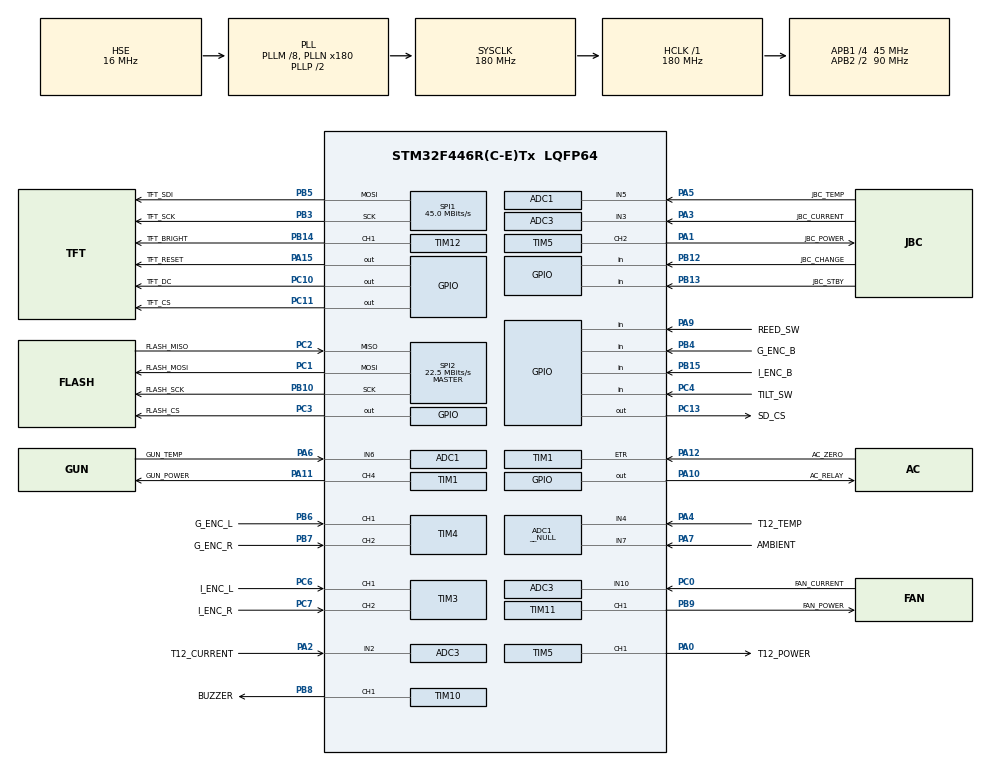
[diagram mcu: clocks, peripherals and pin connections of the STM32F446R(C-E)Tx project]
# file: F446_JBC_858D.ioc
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ADC1.Channel-1\#ChannelRegularConversion=ADC_CHANNEL_4
ADC1.Channel-2\#ChannelRegularConversion=ADC_CHANNEL_7
ADC1.Channel-3\#ChannelRegularConversion=ADC_CHANNEL_VREFINT
ADC1.Channel-4\#ChannelRegularConversion=ADC_CHANNEL_TEMPSENSOR
ADC1.ClockPrescaler=ADC_CLOCK_SYNC_PCLK_DIV4
ADC1.ContinuousConvMode=DISABLE
ADC1.Mode=__NULL
ADC1.NbrOfConversion=4
ADC1.NbrOfConversionFlag=1
ADC1.Rank-1\#ChannelRegularConversion=1
ADC1.Rank-2\#ChannelRegularConversion=2
ADC1.Rank-3\#ChannelRegularConversion=3
ADC1.Rank-4\#ChannelRegularConversion=4
ADC1.SamplingTime-1\#ChannelRegularConversion=ADC_SAMPLETIME_480CYCLES
ADC1.SamplingTime-2\#ChannelRegularConversion=ADC_SAMPLETIME_480CYCLES
ADC1.SamplingTime-3\#ChannelRegularConversion=ADC_SAMPLETIME_480CYCLES
ADC1.SamplingTime-4\#ChannelRegularConversion=ADC_SAMPLETIME_480CYCLES
ADC1.master=1
ADC2.Channel-0\#ChannelRegularConversion=ADC_CHANNEL_5
ADC2.Channel-1\#ChannelRegularConversion=ADC_CHANNEL_6
ADC2.ContinuousConvMode=DISABLE
ADC2.NbrOfConversion=2
ADC2.NbrOfConversionFlag=1
ADC2.Rank-0\#ChannelRegularConversion=1
ADC2.Rank-1\#ChannelRegularConversion=2
ADC2.SamplingTime-0\#ChannelRegularConversion=ADC_SAMPLETIME_480CYCLES
ADC2.SamplingTime-1\#ChannelRegularConversion=ADC_SAMPLETIME_144CYCLES
ADC3.Channel-0\#ChannelRegularConversion=ADC_CHANNEL_2
ADC3.Channel-1\#ChannelRegularConversion=ADC_CHANNEL_3
ADC3.Channel-2\#ChannelRegularConversion=ADC_CHANNEL_10
ADC3.NbrOfConversion=3
ADC3.NbrOfConversionFlag=1
ADC3.Rank-0\#ChannelRegularConversion=1
ADC3.Rank-1\#ChannelRegularConversion=2
ADC3.Rank-2\#ChannelRegularConversion=3
ADC3.SamplingTime-0\#ChannelRegularConversion=ADC_SAMPLETIME_144CYCLES
ADC3.SamplingTime-1\#ChannelRegularConversion=ADC_SAMPLETIME_144CYCLES
ADC3.SamplingTime-2\#ChannelRegularConversion=ADC_SAMPLETIME_144CYCLES
Dma.ADC1.1.Direction=DMA_PERIPH_TO_MEMORY
Dma.ADC1.1.FIFOMode=DMA_FIFOMODE_DISABLE
Dma.ADC1.1.Instance=DMA2_Stream0
Dma.ADC1.1.MemDataAlignment=DMA_MDATAALIGN_HALFWORD
Dma.ADC1.1.MemInc=DMA_MINC_ENABLE
Dma.ADC1.1.Mode=DMA_NORMAL
Dma.ADC1.1.PeriphDataAlignment=DMA_PDATAALIGN_HALFWORD
Dma.ADC1.1.PeriphInc=DMA_PINC_DISABLE
Dma.ADC1.1.Priority=DMA_PRIORITY_LOW
Dma.ADC2.3.Direction=DMA_PERIPH_TO_MEMORY
Dma.ADC2.3.FIFOMode=DMA_FIFOMODE_DISABLE
Dma.ADC2.3.Instance=DMA2_Stream2
Dma.ADC2.3.MemDataAlignment=DMA_MDATAALIGN_HALFWORD
Dma.ADC2.3.MemInc=DMA_MINC_ENABLE
Dma.ADC2.3.Mode=DMA_NORMAL
Dma.ADC2.3.PeriphDataAlignment=DMA_PDATAALIGN_HALFWORD
Dma.ADC2.3.PeriphInc=DMA_PINC_DISABLE
Dma.ADC2.3.Priority=DMA_PRIORITY_LOW
Dma.ADC3.0.Direction=DMA_PERIPH_TO_MEMORY
Dma.ADC3.0.FIFOMode=DMA_FIFOMODE_DISABLE
Dma.ADC3.0.Instance=DMA2_Stream1
Dma.ADC3.0.MemDataAlignment=DMA_MDATAALIGN_HALFWORD
Dma.ADC3.0.MemInc=DMA_MINC_ENABLE
Dma.ADC3.0.Mode=DMA_NORMAL
Dma.ADC3.0.PeriphDataAlignment=DMA_PDATAALIGN_HALFWORD
Dma.ADC3.0.PeriphInc=DMA_PINC_DISABLE
Dma.ADC3.0.Priority=DMA_PRIORITY_LOW
Dma.Request0=ADC3
Dma.Request1=ADC1
Dma.Request2=SPI1_TX
Dma.Request3=ADC2
Dma.Request4=TIM1_CH4/TRIG/COM
Dma.SPI1_TX.2.Direction=DMA_MEMORY_TO_PERIPH
Dma.SPI1_TX.2.FIFOMode=DMA_FIFOMODE_DISABLE
Dma.SPI1_TX.2.Instance=DMA2_Stream3
Dma.SPI1_TX.2.MemDataAlignment=DMA_MDATAALIGN_BYTE
Dma.SPI1_TX.2.MemInc=DMA_MINC_ENABLE
Dma.SPI1_TX.2.Mode=DMA_NORMAL
Dma.SPI1_TX.2.PeriphDataAlignment=DMA_PDATAALIGN_BYTE
Dma.SPI1_TX.2.PeriphInc=DMA_PINC_DISABLE
Dma.SPI1_TX.2.Priority=DMA_PRIORITY_LOW
Dma.TIM1_CH4/TRIG/COM.4.Direction=DMA_MEMORY_TO_PERIPH
Dma.TIM1_CH4/TRIG/COM.4.FIFOMode=DMA_FIFOMODE_DISABLE
Dma.TIM1_CH4/TRIG/COM.4.Instance=DMA2_Stream4
Dma.TIM1_CH4/TRIG/COM.4.MemDataAlignment=DMA_MDATAALIGN_HALFWORD
Dma.TIM1_CH4/TRIG/COM.4.MemInc=DMA_MINC_ENABLE
Dma.TIM1_CH4/TRIG/COM.4.Mode=DMA_CIRCULAR
Dma.TIM1_CH4/TRIG/COM.4.PeriphDataAlignment=DMA_PDATAALIGN_HALFWORD
Dma.TIM1_CH4/TRIG/COM.4.PeriphInc=DMA_PINC_DISABLE
Dma.TIM1_CH4/TRIG/COM.4.Priority=DMA_PRIORITY_LOW
Mcu.Family=STM32F4
Mcu.Name=STM32F446R(C-E)Tx
Mcu.Package=LQFP64
NVIC.DMA2_Stream0_IRQn=true\:0\:0\:false\:false\:true\:false\:true\:true
NVIC.DMA2_Stream1_IRQn=true\:0\:0\:false\:false\:true\:false\:true\:true
NVIC.DMA2_Stream2_IRQn=true\:0\:0\:false\:false\:true\:false\:true\:true
NVIC.DMA2_Stream3_IRQn=true\:2\:0\:true\:false\:true\:false\:true\:true
NVIC.DMA2_Stream4_IRQn=true\:0\:0\:false\:false\:true\:false\:true\:true
NVIC.PriorityGroup=NVIC_PRIORITYGROUP_4
NVIC.TIM1_UP_TIM10_IRQn=true\:0\:0\:false\:false\:true\:true\:true\:true
NVIC.TIM5_IRQn=true\:0\:0\:false\:false\:true\:true\:true\:true
NVIC.TIM7_IRQn=true\:0\:0\:false\:false\:true\:true\:true\:true
PA0-WKUP.GPIO_Label=T12_POWER
PA0-WKUP.Signal=S_TIM5_CH1
PA1.GPIO_Label=JBC_POWER
PA1.Signal=S_TIM5_CH2
PA10.GPIO_Label=AC_RELAY
PA10.Signal=GPIO_Output
PA11.GPIO_Label=GUN_POWER
PA11.Signal=S_TIM1_CH4
PA12.GPIO_Label=AC_ZERO
PA12.Signal=S_TIM1_ETR
PA13.Mode=Serial_Wire
PA13.Signal=SYS_JTMS-SWDIO
PA14.Mode=Serial_Wire
PA14.Signal=SYS_JTCK-SWCLK
PA15.GPIO_Label=TFT_RESET
PA15.Signal=GPIO_Output
PA2.GPIO_Label=T12_CURRENT
PA2.Signal=ADCx_IN2
PA3.GPIO_Label=JBC_CURRENT
PA3.Signal=ADCx_IN3
PA4.GPIO_Label=T12_TEMP
PA4.Signal=ADCx_IN4
PA5.GPIO_Label=JBC_TEMP
PA5.Signal=ADCx_IN5
PA6.GPIO_Label=GUN_TEMP
PA6.Signal=ADCx_IN6
PA7.GPIO_Label=AMBIENT
PA7.Signal=ADCx_IN7
PA9.GPIO_Label=REED_SW
PA9.Signal=GPIO_Input
PB10.GPIO_Label=FLASH_SCK
PB10.Mode=Full_Duplex_Master
PB10.Signal=SPI2_SCK
PB12.GPIO_Label=JBC_CHANGE
PB12.Signal=GPIO_Input
PB13.GPIO_Label=JBC_STBY
PB13.Signal=GPIO_Input
PB14.GPIO_Label=TFT_BRIGHT
PB14.Signal=S_TIM12_CH1
PB15.GPIO_Label=I_ENC_B
PB15.Signal=GPIO_Input
PB3.GPIO_Label=TFT_SCK
PB3.Mode=TX_Only_Simplex_Unidirect_Master
PB3.Signal=SPI1_SCK
PB4.GPIO_Label=G_ENC_B
PB4.Signal=GPIO_Input
PB5.GPIO_Label=TFT_SDI
PB5.Mode=TX_Only_Simplex_Unidirect_Master
PB5.Signal=SPI1_MOSI
PB6.GPIO_Label=G_ENC_L
PB6.Signal=S_TIM4_CH1
PB7.GPIO_Label=G_ENC_R
PB7.Signal=S_TIM4_CH2
PB8.GPIO_Label=BUZZER
PB8.Signal=S_TIM10_CH1
PB9.GPIO_Label=FAN_POWER
PB9.Signal=S_TIM11_CH1
PC0.GPIO_Label=FAN_CURRENT
PC0.Signal=ADCx_IN10
PC1.GPIO_Label=FLASH_MOSI
PC1.Mode=Full_Duplex_Master
PC1.Signal=SPI2_MOSI
PC10.GPIO_Label=TFT_DC
PC10.Signal=GPIO_Output
PC11.GPIO_Label=TFT_CS
PC11.Signal=GPIO_Output
PC13.GPIO_Label=SD_CS
PC13.Signal=GPIO_Output
PC2.GPIO_Label=FLASH_MISO
PC2.Mode=Full_Duplex_Master
PC2.Signal=SPI2_MISO
PC3.GPIO_Label=FLASH_CS
PC3.Signal=GPIO_Output
PC4.GPIO_Label=TILT_SW
PC4.Signal=GPIO_Input
PC6.GPIO_Label=I_ENC_L
PC6.Signal=S_TIM3_CH1
PC7.GPIO_Label=I_ENC_R
PC7.Signal=S_TIM3_CH2
PH0-OSC_IN.Mode=HSE-External-Oscillator
PH0-OSC_IN.Signal=RCC_OSC_IN
PH1-OSC_OUT.Mode=HSE-External-Oscillator
PH1-OSC_OUT.Signal=RCC_OSC_OUT
ProjectManager.HeapSize=0x200
ProjectManager.StackSize=0x400
ProjectManager.TargetToolchain=STM32CubeIDE
RCC.AHBFreq_Value=180000000
RCC.APB1CLKDivider=RCC_HCLK_DIV4
RCC.APB1Freq_Value=45000000
RCC.APB1TimFreq_Value=90000000
RCC.APB2CLKDivider=RCC_HCLK_DIV2
RCC.APB2Freq_Value=90000000
RCC.APB2TimFreq_Value=180000000
RCC.CortexFreq_Value=180000000
RCC.HCLKFreq_Value=180000000
RCC.HSE_VALUE=16000000
RCC.PLLM=8
RCC.PLLN=180
RCC.PLLSourceVirtual=RCC_PLLSOURCE_HSE
RCC.SYSCLKFreq_VALUE=180000000
RCC.SYSCLKSource=RCC_SYSCLKSOURCE_PLLCLK
RCC.USBFreq_Value=180000000
RCC.VCOOutputFreq_Value=360000000
SH.ADCx_IN10.0=ADC3_IN10,IN10
SH.ADCx_IN2.0=ADC3_IN2,IN2
SH.ADCx_IN3.0=ADC3_IN3,IN3
SH.ADCx_IN4.0=ADC1_IN4,IN4
SH.ADCx_IN4.1=ADC2_IN4,IN4
SH.ADCx_IN5.0=ADC1_IN5,IN5
SH.ADCx_IN5.1=ADC2_IN5,IN5
SH.ADCx_IN6.0=ADC1_IN6,IN6
SH.ADCx_IN6.1=ADC2_IN6,IN6
SH.ADCx_IN7.0=ADC1_IN7,IN7
SH.ADCx_IN7.1=ADC2_IN7,IN7
SH.S_TIM10_CH1.0=TIM10_CH1,PWM Generation1 CH1
SH.S_TIM11_CH1.0=TIM11_CH1,PWM Generation1 CH1
SH.S_TIM12_CH1.0=TIM12_CH1,PWM Generation1 CH1
SH.S_TIM1_CH4.0=TIM1_CH4,PWM Generation4 CH4
SH.S_TIM1_ETR.0=TIM1_ETR,TriggerSource_ETR
SH.S_TIM3_CH1.0=TIM3_CH1,Encoder_Interface
SH.S_TIM3_CH2.0=TIM3_CH2,Encoder_Interface
SH.S_TIM4_CH1.0=TIM4_CH1,Encoder_Interface
SH.S_TIM4_CH2.0=TIM4_CH2,Encoder_Interface
SH.S_TIM5_CH1.0=TIM5_CH1,PWM Generation1 CH1
SH.S_TIM5_CH2.0=TIM5_CH2,PWM Generation2 CH2
SPI1.BaudRatePrescaler=SPI_BAUDRATEPRESCALER_2
SPI1.CalculateBaudRate=45.0 MBits/s
SPI1.Direction=SPI_DIRECTION_2LINES
SPI1.Mode=SPI_MODE_MASTER
SPI1.VirtualType=VM_MASTER
SPI2.BaudRatePrescaler=SPI_BAUDRATEPRESCALER_2
SPI2.CalculateBaudRate=22.5 MBits/s
SPI2.Direction=SPI_DIRECTION_2LINES
SPI2.Mode=SPI_MODE_MASTER
SPI2.VirtualType=VM_MASTER
TIM1.Channel-PWM\ Generation4\ CH4=TIM_CHANNEL_4
TIM1.ClockDivision=TIM_CLOCKDIVISION_DIV4
TIM1.Period=255
TIM1.Prescaler=17999
TIM1.Slave_TriggerFilter=7
TIM10.Channel=TIM_CHANNEL_1
TIM10.Prescaler=179
TIM11.Channel=TIM_CHANNEL_1
TIM11.Period=1999
TIM11.Prescaler=9
TIM12.Channel-PWM\ Generation1\ CH1=TIM_CHANNEL_1
TIM12.OCPolarity_1=TIM_OCPOLARITY_LOW
TIM12.Period=255
TIM12.Prescaler=777
TIM3.IC1Filter=7
TIM3.IC2Filter=7
TIM4.IC1Filter=7
TIM4.IC2Filter=7
TIM5.Channel-Output\ Compare3\ No\ Output=TIM_CHANNEL_3
TIM5.Channel-Output\ Compare4\ No\ Output=TIM_CHANNEL_4
TIM5.Channel-PWM\ Generation1\ CH1=TIM_CHANNEL_1
TIM5.Channel-PWM\ Generation2\ CH2=TIM_CHANNEL_2
TIM5.Period=1999
TIM5.Prescaler=899
TIM5.Pulse-Output\ Compare3\ No\ Output=1
TIM5.Pulse-Output\ Compare4\ No\ Output=1980
TIM7.Prescaler=8999
VP_ADC1_TempSens_Input.Mode=IN-TempSens
VP_ADC1_Vref_Input.Mode=IN-Vrefint
VP_TIM10_VS_ClockSourceINT.Mode=Enable_Timer
VP_TIM11_VS_ClockSourceINT.Mode=Enable_Timer
VP_TIM12_VS_ClockSourceINT.Mode=Internal
VP_TIM1_VS_ClockSourceINT.Mode=Internal
VP_TIM1_VS_ControllerModeReset.Mode=Reset Mode
VP_TIM5_VS_ClockSourceINT.Mode=Internal
VP_TIM5_VS_no_output3.Mode=Output Compare3 No Output
VP_TIM5_VS_no_output4.Mode=Output Compare4 No Output
VP_TIM7_VS_ClockSourceINT.Mode=Enable_Timer
board=custom

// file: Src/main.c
/* USER CODE BEGIN Header */
/**
  ******************************************************************************
  * @file           : main.c
  * @brief          : Main program body
  ******************************************************************************
  * @attention
  *
  * Copyright (c) 2022 STMicroelectronics.
  * All rights reserved.
  *
  * This software is licensed under terms that can be found in the LICENSE file
  * in the root directory of this software component.
  * If no LICENSE file comes with this software, it is provided AS-IS.
  *
  ******************************************************************************
  *
  * DONE OCT 06 2024, v.1.07:
  *  Fast Hot Gun cooling
  *  The GUN detection bug fixed at GUN PID tune procedure.
  *
  */
/* USER CODE END Header */
#include "main.h"

/* USER CODE BEGIN Includes */
#include "core.h"

/* USER CODE END Includes */

ADC_HandleTypeDef hadc1;
ADC_HandleTypeDef hadc2;
ADC_HandleTypeDef hadc3;
DMA_HandleTypeDef hdma_adc1;
DMA_HandleTypeDef hdma_adc2;
DMA_HandleTypeDef hdma_adc3;

SPI_HandleTypeDef hspi1;
SPI_HandleTypeDef hspi2;
DMA_HandleTypeDef hdma_spi1_tx;

TIM_HandleTypeDef htim1;
TIM_HandleTypeDef htim3;
TIM_HandleTypeDef htim4;
TIM_HandleTypeDef htim5;
TIM_HandleTypeDef htim7;
TIM_HandleTypeDef htim10;
TIM_HandleTypeDef htim11;
TIM_HandleTypeDef htim12;
DMA_HandleTypeDef hdma_tim1_ch4_trig_com;

void SystemClock_Config(void);
static void MX_GPIO_Init(void);
static void MX_DMA_Init(void);
static void MX_ADC1_Init(void);
static void MX_ADC2_Init(void);
static void MX_ADC3_Init(void);
static void MX_TIM1_Init(void);
static void MX_TIM5_Init(void);
static void MX_SPI1_Init(void);
static void MX_SPI2_Init(void);
static void MX_TIM3_Init(void);
static void MX_TIM4_Init(void);
static void MX_TIM10_Init(void);
static void MX_TIM11_Init(void);
static void MX_TIM12_Init(void);
static void MX_TIM7_Init(void);

int main(void)
{

  /* MCU Configuration--------------------------------------------------------*/

  /* Reset of all peripherals, Initializes the Flash interface and the Systick. */
  HAL_Init();

  /* Configure the system clock */
  SystemClock_Config();

  /* Initialize all configured peripherals */
  MX_GPIO_Init();
  MX_DMA_Init();
  MX_ADC1_Init();
  MX_ADC2_Init();
  MX_ADC3_Init();
  MX_TIM1_Init();
  MX_TIM5_Init();
  MX_SPI1_Init();
  MX_SPI2_Init();
  MX_TIM3_Init();
  MX_TIM4_Init();
  MX_TIM10_Init();
  MX_TIM11_Init();
  MX_TIM12_Init();
  MX_TIM7_Init();
  /* USER CODE BEGIN 2 */
  setup();
  /* USER CODE END 2 */

  /* Infinite loop */
  while (1)
  {

    /* USER CODE BEGIN 3 */
	  loop();

  }
  /* USER CODE END 3 */
}

void SystemClock_Config(void)
{
  RCC_OscInitTypeDef RCC_OscInitStruct = {0};
  RCC_ClkInitTypeDef RCC_ClkInitStruct = {0};

  /** Configure the main internal regulator output voltage
  */
  __HAL_RCC_PWR_CLK_ENABLE();
  __HAL_PWR_VOLTAGESCALING_CONFIG(PWR_REGULATOR_VOLTAGE_SCALE1);

  /** Initializes the RCC Oscillators according to the specified parameters
  * in the RCC_OscInitTypeDef structure.
  */
  RCC_OscInitStruct.OscillatorType = RCC_OSCILLATORTYPE_HSE;
  RCC_OscInitStruct.HSEState = RCC_HSE_ON;
  RCC_OscInitStruct.PLL.PLLState = RCC_PLL_ON;
  RCC_OscInitStruct.PLL.PLLSource = RCC_PLLSOURCE_HSE;
  RCC_OscInitStruct.PLL.PLLM = 8;
  RCC_OscInitStruct.PLL.PLLN = 180;
  RCC_OscInitStruct.PLL.PLLP = RCC_PLLP_DIV2;
  RCC_OscInitStruct.PLL.PLLQ = 2;
  RCC_OscInitStruct.PLL.PLLR = 2;
  if (HAL_RCC_OscConfig(&RCC_OscInitStruct) != HAL_OK)
  {
    Error_Handler();
  }

  /** Activate the Over-Drive mode
  */
  if (HAL_PWREx_EnableOverDrive() != HAL_OK)
  {
    Error_Handler();
  }

  /** Initializes the CPU, AHB and APB buses clocks
  */
  RCC_ClkInitStruct.ClockType = RCC_CLOCKTYPE_HCLK|RCC_CLOCKTYPE_SYSCLK
                              |RCC_CLOCKTYPE_PCLK1|RCC_CLOCKTYPE_PCLK2;
  RCC_ClkInitStruct.SYSCLKSource = RCC_SYSCLKSOURCE_PLLCLK;
  RCC_ClkInitStruct.AHBCLKDivider = RCC_SYSCLK_DIV1;
  RCC_ClkInitStruct.APB1CLKDivider = RCC_HCLK_DIV4;
  RCC_ClkInitStruct.APB2CLKDivider = RCC_HCLK_DIV2;

  if (HAL_RCC_ClockConfig(&RCC_ClkInitStruct, FLASH_LATENCY_5) != HAL_OK)
  {
    Error_Handler();
  }
}

static void MX_ADC1_Init(void)
{

  ADC_ChannelConfTypeDef sConfig = {0};

  /** Configure the global features of the ADC (Clock, Resolution, Data Alignment and number of conversion)
  */
  hadc1.Instance = ADC1;
  hadc1.Init.ClockPrescaler = ADC_CLOCK_SYNC_PCLK_DIV4;
  hadc1.Init.Resolution = ADC_RESOLUTION_12B;
  hadc1.Init.ScanConvMode = ENABLE;
  hadc1.Init.ContinuousConvMode = DISABLE;
  hadc1.Init.DiscontinuousConvMode = DISABLE;
  hadc1.Init.ExternalTrigConvEdge = ADC_EXTERNALTRIGCONVEDGE_NONE;
  hadc1.Init.ExternalTrigConv = ADC_SOFTWARE_START;
  hadc1.Init.DataAlign = ADC_DATAALIGN_RIGHT;
  hadc1.Init.NbrOfConversion = 4;
  hadc1.Init.DMAContinuousRequests = DISABLE;
  hadc1.Init.EOCSelection = ADC_EOC_SINGLE_CONV;
  if (HAL_ADC_Init(&hadc1) != HAL_OK)
  {
    Error_Handler();
  }

  /** Configure for the selected ADC regular channel its corresponding rank in the sequencer and its sample time.
  */
  sConfig.Channel = ADC_CHANNEL_4;
  sConfig.Rank = 1;
  sConfig.SamplingTime = ADC_SAMPLETIME_480CYCLES;
  if (HAL_ADC_ConfigChannel(&hadc1, &sConfig) != HAL_OK)
  {
    Error_Handler();
  }

  /** Configure for the selected ADC regular channel its corresponding rank in the sequencer and its sample time.
  */
  sConfig.Channel = ADC_CHANNEL_7;
  sConfig.Rank = 2;
  if (HAL_ADC_ConfigChannel(&hadc1, &sConfig) != HAL_OK)
  {
    Error_Handler();
  }

  /** Configure for the selected ADC regular channel its corresponding rank in the sequencer and its sample time.
  */
  sConfig.Channel = ADC_CHANNEL_VREFINT;
  sConfig.Rank = 3;
  if (HAL_ADC_ConfigChannel(&hadc1, &sConfig) != HAL_OK)
  {
    Error_Handler();
  }

  /** Configure for the selected ADC regular channel its corresponding rank in the sequencer and its sample time.
  */
  sConfig.Channel = ADC_CHANNEL_TEMPSENSOR;
  sConfig.Rank = 4;
  if (HAL_ADC_ConfigChannel(&hadc1, &sConfig) != HAL_OK)
  {
    Error_Handler();
  }

}

static void MX_ADC2_Init(void)
{

  ADC_ChannelConfTypeDef sConfig = {0};

  /** Configure the global features of the ADC (Clock, Resolution, Data Alignment and number of conversion)
  */
  hadc2.Instance = ADC2;
  hadc2.Init.ClockPrescaler = ADC_CLOCK_SYNC_PCLK_DIV4;
  hadc2.Init.Resolution = ADC_RESOLUTION_12B;
  hadc2.Init.ScanConvMode = ENABLE;
  hadc2.Init.ContinuousConvMode = DISABLE;
  hadc2.Init.DiscontinuousConvMode = DISABLE;
  hadc2.Init.ExternalTrigConvEdge = ADC_EXTERNALTRIGCONVEDGE_NONE;
  hadc2.Init.ExternalTrigConv = ADC_SOFTWARE_START;
  hadc2.Init.DataAlign = ADC_DATAALIGN_RIGHT;
  hadc2.Init.NbrOfConversion = 2;
  hadc2.Init.DMAContinuousRequests = DISABLE;
  hadc2.Init.EOCSelection = ADC_EOC_SINGLE_CONV;
  if (HAL_ADC_Init(&hadc2) != HAL_OK)
  {
    Error_Handler();
  }

  /** Configure for the selected ADC regular channel its corresponding rank in the sequencer and its sample time.
  */
  sConfig.Channel = ADC_CHANNEL_5;
  sConfig.Rank = 1;
  sConfig.SamplingTime = ADC_SAMPLETIME_480CYCLES;
  if (HAL_ADC_ConfigChannel(&hadc2, &sConfig) != HAL_OK)
  {
    Error_Handler();
  }

  /** Configure for the selected ADC regular channel its corresponding rank in the sequencer and its sample time.
  */
  sConfig.Channel = ADC_CHANNEL_6;
  sConfig.Rank = 2;
  sConfig.SamplingTime = ADC_SAMPLETIME_144CYCLES;
  if (HAL_ADC_ConfigChannel(&hadc2, &sConfig) != HAL_OK)
  {
    Error_Handler();
  }

}

static void MX_ADC3_Init(void)
{

  ADC_ChannelConfTypeDef sConfig = {0};

  /** Configure the global features of the ADC (Clock, Resolution, Data Alignment and number of conversion)
  */
  hadc3.Instance = ADC3;
  hadc3.Init.ClockPrescaler = ADC_CLOCK_SYNC_PCLK_DIV4;
  hadc3.Init.Resolution = ADC_RESOLUTION_12B;
  hadc3.Init.ScanConvMode = ENABLE;
  hadc3.Init.ContinuousConvMode = DISABLE;
  hadc3.Init.DiscontinuousConvMode = DISABLE;
  hadc3.Init.ExternalTrigConvEdge = ADC_EXTERNALTRIGCONVEDGE_NONE;
  hadc3.Init.ExternalTrigConv = ADC_SOFTWARE_START;
  hadc3.Init.DataAlign = ADC_DATAALIGN_RIGHT;
  hadc3.Init.NbrOfConversion = 3;
  hadc3.Init.DMAContinuousRequests = DISABLE;
  hadc3.Init.EOCSelection = ADC_EOC_SINGLE_CONV;
  if (HAL_ADC_Init(&hadc3) != HAL_OK)
  {
    Error_Handler();
  }

  /** Configure for the selected ADC regular channel its corresponding rank in the sequencer and its sample time.
  */
  sConfig.Channel = ADC_CHANNEL_2;
  sConfig.Rank = 1;
  sConfig.SamplingTime = ADC_SAMPLETIME_144CYCLES;
  if (HAL_ADC_ConfigChannel(&hadc3, &sConfig) != HAL_OK)
  {
    Error_Handler();
  }

  /** Configure for the selected ADC regular channel its corresponding rank in the sequencer and its sample time.
  */
  sConfig.Channel = ADC_CHANNEL_3;
  sConfig.Rank = 2;
  if (HAL_ADC_ConfigChannel(&hadc3, &sConfig) != HAL_OK)
  {
    Error_Handler();
  }

  /** Configure for the selected ADC regular channel its corresponding rank in the sequencer and its sample time.
  */
  sConfig.Channel = ADC_CHANNEL_10;
  sConfig.Rank = 3;
  if (HAL_ADC_ConfigChannel(&hadc3, &sConfig) != HAL_OK)
  {
    Error_Handler();
  }

}

static void MX_SPI1_Init(void)
{

  /* SPI1 parameter configuration*/
  hspi1.Instance = SPI1;
  hspi1.Init.Mode = SPI_MODE_MASTER;
  hspi1.Init.Direction = SPI_DIRECTION_2LINES;
  hspi1.Init.DataSize = SPI_DATASIZE_8BIT;
  hspi1.Init.CLKPolarity = SPI_POLARITY_LOW;
  hspi1.Init.CLKPhase = SPI_PHASE_1EDGE;
  hspi1.Init.NSS = SPI_NSS_SOFT;
  hspi1.Init.BaudRatePrescaler = SPI_BAUDRATEPRESCALER_2;
  hspi1.Init.FirstBit = SPI_FIRSTBIT_MSB;
  hspi1.Init.TIMode = SPI_TIMODE_DISABLE;
  hspi1.Init.CRCCalculation = SPI_CRCCALCULATION_DISABLE;
  hspi1.Init.CRCPolynomial = 10;
  if (HAL_SPI_Init(&hspi1) != HAL_OK)
  {
    Error_Handler();
  }

}

static void MX_SPI2_Init(void)
{

  /* SPI2 parameter configuration*/
  hspi2.Instance = SPI2;
  hspi2.Init.Mode = SPI_MODE_MASTER;
  hspi2.Init.Direction = SPI_DIRECTION_2LINES;
  hspi2.Init.DataSize = SPI_DATASIZE_8BIT;
  hspi2.Init.CLKPolarity = SPI_POLARITY_LOW;
  hspi2.Init.CLKPhase = SPI_PHASE_1EDGE;
  hspi2.Init.NSS = SPI_NSS_SOFT;
  hspi2.Init.BaudRatePrescaler = SPI_BAUDRATEPRESCALER_2;
  hspi2.Init.FirstBit = SPI_FIRSTBIT_MSB;
  hspi2.Init.TIMode = SPI_TIMODE_DISABLE;
  hspi2.Init.CRCCalculation = SPI_CRCCALCULATION_DISABLE;
  hspi2.Init.CRCPolynomial = 10;
  if (HAL_SPI_Init(&hspi2) != HAL_OK)
  {
    Error_Handler();
  }

}

static void MX_TIM1_Init(void)
{

  TIM_ClockConfigTypeDef sClockSourceConfig = {0};
  TIM_SlaveConfigTypeDef sSlaveConfig = {0};
  TIM_MasterConfigTypeDef sMasterConfig = {0};
  TIM_OC_InitTypeDef sConfigOC = {0};
  TIM_BreakDeadTimeConfigTypeDef sBreakDeadTimeConfig = {0};

  htim1.Instance = TIM1;
  htim1.Init.Prescaler = 17999;
  htim1.Init.CounterMode = TIM_COUNTERMODE_UP;
  htim1.Init.Period = 255;
  htim1.Init.ClockDivision = TIM_CLOCKDIVISION_DIV4;
  htim1.Init.RepetitionCounter = 0;
  htim1.Init.AutoReloadPreload = TIM_AUTORELOAD_PRELOAD_DISABLE;
  if (HAL_TIM_Base_Init(&htim1) != HAL_OK)
  {
    Error_Handler();
  }
  sClockSourceConfig.ClockSource = TIM_CLOCKSOURCE_INTERNAL;
  if (HAL_TIM_ConfigClockSource(&htim1, &sClockSourceConfig) != HAL_OK)
  {
    Error_Handler();
  }
  if (HAL_TIM_PWM_Init(&htim1) != HAL_OK)
  {
    Error_Handler();
  }
  sSlaveConfig.SlaveMode = TIM_SLAVEMODE_RESET;
  sSlaveConfig.InputTrigger = TIM_TS_ETRF;
  sSlaveConfig.TriggerPolarity = TIM_TRIGGERPOLARITY_NONINVERTED;
  sSlaveConfig.TriggerPrescaler = TIM_TRIGGERPRESCALER_DIV1;
  sSlaveConfig.TriggerFilter = 7;
  if (HAL_TIM_SlaveConfigSynchro(&htim1, &sSlaveConfig) != HAL_OK)
  {
    Error_Handler();
  }
  sMasterConfig.MasterOutputTrigger = TIM_TRGO_RESET;
  sMasterConfig.MasterSlaveMode = TIM_MASTERSLAVEMODE_DISABLE;
  if (HAL_TIMEx_MasterConfigSynchronization(&htim1, &sMasterConfig) != HAL_OK)
  {
    Error_Handler();
  }
  sConfigOC.OCMode = TIM_OCMODE_PWM1;
  sConfigOC.Pulse = 0;
  sConfigOC.OCPolarity = TIM_OCPOLARITY_HIGH;
  sConfigOC.OCFastMode = TIM_OCFAST_DISABLE;
  sConfigOC.OCIdleState = TIM_OCIDLESTATE_RESET;
  sConfigOC.OCNIdleState = TIM_OCNIDLESTATE_RESET;
  if (HAL_TIM_PWM_ConfigChannel(&htim1, &sConfigOC, TIM_CHANNEL_4) != HAL_OK)
  {
    Error_Handler();
  }
  sBreakDeadTimeConfig.OffStateRunMode = TIM_OSSR_DISABLE;
  sBreakDeadTimeConfig.OffStateIDLEMode = TIM_OSSI_DISABLE;
  sBreakDeadTimeConfig.LockLevel = TIM_LOCKLEVEL_OFF;
  sBreakDeadTimeConfig.DeadTime = 0;
  sBreakDeadTimeConfig.BreakState = TIM_BREAK_DISABLE;
  sBreakDeadTimeConfig.BreakPolarity = TIM_BREAKPOLARITY_HIGH;
  sBreakDeadTimeConfig.AutomaticOutput = TIM_AUTOMATICOUTPUT_DISABLE;
  if (HAL_TIMEx_ConfigBreakDeadTime(&htim1, &sBreakDeadTimeConfig) != HAL_OK)
  {
    Error_Handler();
  }
  HAL_TIM_MspPostInit(&htim1);

}

static void MX_TIM3_Init(void)
{

  TIM_Encoder_InitTypeDef sConfig = {0};
  TIM_MasterConfigTypeDef sMasterConfig = {0};

  htim3.Instance = TIM3;
  htim3.Init.Prescaler = 0;
  htim3.Init.CounterMode = TIM_COUNTERMODE_UP;
  htim3.Init.Period = 65535;
  htim3.Init.ClockDivision = TIM_CLOCKDIVISION_DIV1;
  htim3.Init.AutoReloadPreload = TIM_AUTORELOAD_PRELOAD_DISABLE;
  sConfig.EncoderMode = TIM_ENCODERMODE_TI1;
  sConfig.IC1Polarity = TIM_ICPOLARITY_RISING;
  sConfig.IC1Selection = TIM_ICSELECTION_DIRECTTI;
  sConfig.IC1Prescaler = TIM_ICPSC_DIV1;
  sConfig.IC1Filter = 7;
  sConfig.IC2Polarity = TIM_ICPOLARITY_RISING;
  sConfig.IC2Selection = TIM_ICSELECTION_DIRECTTI;
  sConfig.IC2Prescaler = TIM_ICPSC_DIV1;
  sConfig.IC2Filter = 7;
  if (HAL_TIM_Encoder_Init(&htim3, &sConfig) != HAL_OK)
  {
    Error_Handler();
  }
  sMasterConfig.MasterOutputTrigger = TIM_TRGO_RESET;
  sMasterConfig.MasterSlaveMode = TIM_MASTERSLAVEMODE_DISABLE;
  if (HAL_TIMEx_MasterConfigSynchronization(&htim3, &sMasterConfig) != HAL_OK)
  {
    Error_Handler();
  }

}

static void MX_TIM4_Init(void)
{

  TIM_Encoder_InitTypeDef sConfig = {0};
  TIM_MasterConfigTypeDef sMasterConfig = {0};

  htim4.Instance = TIM4;
  htim4.Init.Prescaler = 0;
  htim4.Init.CounterMode = TIM_COUNTERMODE_UP;
  htim4.Init.Period = 65535;
  htim4.Init.ClockDivision = TIM_CLOCKDIVISION_DIV1;
  htim4.Init.AutoReloadPreload = TIM_AUTORELOAD_PRELOAD_DISABLE;
  sConfig.EncoderMode = TIM_ENCODERMODE_TI1;
  sConfig.IC1Polarity = TIM_ICPOLARITY_RISING;
  sConfig.IC1Selection = TIM_ICSELECTION_DIRECTTI;
  sConfig.IC1Prescaler = TIM_ICPSC_DIV1;
  sConfig.IC1Filter = 7;
  sConfig.IC2Polarity = TIM_ICPOLARITY_RISING;
  sConfig.IC2Selection = TIM_ICSELECTION_DIRECTTI;
  sConfig.IC2Prescaler = TIM_ICPSC_DIV1;
  sConfig.IC2Filter = 7;
  if (HAL_TIM_Encoder_Init(&htim4, &sConfig) != HAL_OK)
  {
    Error_Handler();
  }
  sMasterConfig.MasterOutputTrigger = TIM_TRGO_RESET;
  sMasterConfig.MasterSlaveMode = TIM_MASTERSLAVEMODE_DISABLE;
  if (HAL_TIMEx_MasterConfigSynchronization(&htim4, &sMasterConfig) != HAL_OK)
  {
    Error_Handler();
  }

}

static void MX_TIM5_Init(void)
{

  TIM_ClockConfigTypeDef sClockSourceConfig = {0};
  TIM_MasterConfigTypeDef sMasterConfig = {0};
  TIM_OC_InitTypeDef sConfigOC = {0};

  htim5.Instance = TIM5;
  htim5.Init.Prescaler = 899;
  htim5.Init.CounterMode = TIM_COUNTERMODE_UP;
  htim5.Init.Period = 1999;
  htim5.Init.ClockDivision = TIM_CLOCKDIVISION_DIV1;
  htim5.Init.AutoReloadPreload = TIM_AUTORELOAD_PRELOAD_DISABLE;
  if (HAL_TIM_Base_Init(&htim5) != HAL_OK)
  {
    Error_Handler();
  }
  sClockSourceConfig.ClockSource = TIM_CLOCKSOURCE_INTERNAL;
  if (HAL_TIM_ConfigClockSource(&htim5, &sClockSourceConfig) != HAL_OK)
  {
    Error_Handler();
  }
  if (HAL_TIM_PWM_Init(&htim5) != HAL_OK)
  {
    Error_Handler();
  }
  if (HAL_TIM_OC_Init(&htim5) != HAL_OK)
  {
    Error_Handler();
  }
  sMasterConfig.MasterOutputTrigger = TIM_TRGO_RESET;
  sMasterConfig.MasterSlaveMode = TIM_MASTERSLAVEMODE_DISABLE;
  if (HAL_TIMEx_MasterConfigSynchronization(&htim5, &sMasterConfig) != HAL_OK)
  {
    Error_Handler();
  }
  sConfigOC.OCMode = TIM_OCMODE_PWM1;
  sConfigOC.Pulse = 0;
  sConfigOC.OCPolarity = TIM_OCPOLARITY_HIGH;
  sConfigOC.OCFastMode = TIM_OCFAST_DISABLE;
  if (HAL_TIM_PWM_ConfigChannel(&htim5, &sConfigOC, TIM_CHANNEL_1) != HAL_OK)
  {
    Error_Handler();
  }
  if (HAL_TIM_PWM_ConfigChannel(&htim5, &sConfigOC, TIM_CHANNEL_2) != HAL_OK)
  {
    Error_Handler();
  }
  sConfigOC.OCMode = TIM_OCMODE_TIMING;
  sConfigOC.Pulse = 1;
  if (HAL_TIM_OC_ConfigChannel(&htim5, &sConfigOC, TIM_CHANNEL_3) != HAL_OK)
  {
    Error_Handler();
  }
  sConfigOC.Pulse = 1980;
  if (HAL_TIM_OC_ConfigChannel(&htim5, &sConfigOC, TIM_CHANNEL_4) != HAL_OK)
  {
    Error_Handler();
  }
  HAL_TIM_MspPostInit(&htim5);

}

static void MX_TIM7_Init(void)
{

  TIM_MasterConfigTypeDef sMasterConfig = {0};

  htim7.Instance = TIM7;
  htim7.Init.Prescaler = 8999;
  htim7.Init.CounterMode = TIM_COUNTERMODE_UP;
  htim7.Init.Period = 65535;
  htim7.Init.AutoReloadPreload = TIM_AUTORELOAD_PRELOAD_DISABLE;
  if (HAL_TIM_Base_Init(&htim7) != HAL_OK)
  {
    Error_Handler();
  }
  sMasterConfig.MasterOutputTrigger = TIM_TRGO_RESET;
  sMasterConfig.MasterSlaveMode = TIM_MASTERSLAVEMODE_DISABLE;
  if (HAL_TIMEx_MasterConfigSynchronization(&htim7, &sMasterConfig) != HAL_OK)
  {
    Error_Handler();
  }

}

static void MX_TIM10_Init(void)
{

  TIM_OC_InitTypeDef sConfigOC = {0};

  htim10.Instance = TIM10;
  htim10.Init.Prescaler = 179;
  htim10.Init.CounterMode = TIM_COUNTERMODE_UP;
  htim10.Init.Period = 65535;
  htim10.Init.ClockDivision = TIM_CLOCKDIVISION_DIV1;
  htim10.Init.AutoReloadPreload = TIM_AUTORELOAD_PRELOAD_DISABLE;
  if (HAL_TIM_Base_Init(&htim10) != HAL_OK)
  {
    Error_Handler();
  }
  if (HAL_TIM_PWM_Init(&htim10) != HAL_OK)
  {
    Error_Handler();
  }
  sConfigOC.OCMode = TIM_OCMODE_PWM1;
  sConfigOC.Pulse = 0;
  sConfigOC.OCPolarity = TIM_OCPOLARITY_HIGH;
  sConfigOC.OCFastMode = TIM_OCFAST_DISABLE;
  if (HAL_TIM_PWM_ConfigChannel(&htim10, &sConfigOC, TIM_CHANNEL_1) != HAL_OK)
  {
    Error_Handler();
  }
  HAL_TIM_MspPostInit(&htim10);

}

static void MX_TIM11_Init(void)
{

  TIM_OC_InitTypeDef sConfigOC = {0};

  htim11.Instance = TIM11;
  htim11.Init.Prescaler = 9;
  htim11.Init.CounterMode = TIM_COUNTERMODE_UP;
  htim11.Init.Period = 1999;
  htim11.Init.ClockDivision = TIM_CLOCKDIVISION_DIV1;
  htim11.Init.AutoReloadPreload = TIM_AUTORELOAD_PRELOAD_DISABLE;
  if (HAL_TIM_Base_Init(&htim11) != HAL_OK)
  {
    Error_Handler();
  }
  if (HAL_TIM_PWM_Init(&htim11) != HAL_OK)
  {
    Error_Handler();
  }
  sConfigOC.OCMode = TIM_OCMODE_PWM1;
  sConfigOC.Pulse = 0;
  sConfigOC.OCPolarity = TIM_OCPOLARITY_HIGH;
  sConfigOC.OCFastMode = TIM_OCFAST_DISABLE;
  if (HAL_TIM_PWM_ConfigChannel(&htim11, &sConfigOC, TIM_CHANNEL_1) != HAL_OK)
  {
    Error_Handler();
  }
  HAL_TIM_MspPostInit(&htim11);

}

static void MX_TIM12_Init(void)
{

  TIM_ClockConfigTypeDef sClockSourceConfig = {0};
  TIM_OC_InitTypeDef sConfigOC = {0};

  htim12.Instance = TIM12;
  htim12.Init.Prescaler = 777;
  htim12.Init.CounterMode = TIM_COUNTERMODE_UP;
  htim12.Init.Period = 255;
  htim12.Init.ClockDivision = TIM_CLOCKDIVISION_DIV1;
  htim12.Init.AutoReloadPreload = TIM_AUTORELOAD_PRELOAD_DISABLE;
  if (HAL_TIM_Base_Init(&htim12) != HAL_OK)
  {
    Error_Handler();
  }
  sClockSourceConfig.ClockSource = TIM_CLOCKSOURCE_INTERNAL;
  if (HAL_TIM_ConfigClockSource(&htim12, &sClockSourceConfig) != HAL_OK)
  {
    Error_Handler();
  }
  if (HAL_TIM_PWM_Init(&htim12) != HAL_OK)
  {
    Error_Handler();
  }
  sConfigOC.OCMode = TIM_OCMODE_PWM1;
  sConfigOC.Pulse = 0;
  sConfigOC.OCPolarity = TIM_OCPOLARITY_LOW;
  sConfigOC.OCFastMode = TIM_OCFAST_DISABLE;
  if (HAL_TIM_PWM_ConfigChannel(&htim12, &sConfigOC, TIM_CHANNEL_1) != HAL_OK)
  {
    Error_Handler();
  }
  HAL_TIM_MspPostInit(&htim12);

}

static void MX_DMA_Init(void)
{

  /* DMA controller clock enable */
  __HAL_RCC_DMA2_CLK_ENABLE();

  /* DMA interrupt init */
  /* DMA2_Stream0_IRQn interrupt configuration */
  HAL_NVIC_SetPriority(DMA2_Stream0_IRQn, 0, 0);
  HAL_NVIC_EnableIRQ(DMA2_Stream0_IRQn);
  /* DMA2_Stream1_IRQn interrupt configuration */
  HAL_NVIC_SetPriority(DMA2_Stream1_IRQn, 0, 0);
  HAL_NVIC_EnableIRQ(DMA2_Stream1_IRQn);
  /* DMA2_Stream2_IRQn interrupt configuration */
  HAL_NVIC_SetPriority(DMA2_Stream2_IRQn, 0, 0);
  HAL_NVIC_EnableIRQ(DMA2_Stream2_IRQn);
  /* DMA2_Stream3_IRQn interrupt configuration */
  HAL_NVIC_SetPriority(DMA2_Stream3_IRQn, 2, 0);
  HAL_NVIC_EnableIRQ(DMA2_Stream3_IRQn);
  /* DMA2_Stream4_IRQn interrupt configuration */
  HAL_NVIC_SetPriority(DMA2_Stream4_IRQn, 0, 0);
  HAL_NVIC_EnableIRQ(DMA2_Stream4_IRQn);

}

static void MX_GPIO_Init(void)
{
  GPIO_InitTypeDef GPIO_InitStruct = {0};

  /* GPIO Ports Clock Enable */
  __HAL_RCC_GPIOC_CLK_ENABLE();
  __HAL_RCC_GPIOH_CLK_ENABLE();
  __HAL_RCC_GPIOA_CLK_ENABLE();
  __HAL_RCC_GPIOB_CLK_ENABLE();

  /*Configure GPIO pin Output Level */
  HAL_GPIO_WritePin(GPIOC, SD_CS_Pin|FLASH_CS_Pin|TFT_DC_Pin|TFT_CS_Pin, GPIO_PIN_RESET);

  /*Configure GPIO pin Output Level */
  HAL_GPIO_WritePin(GPIOA, AC_RELAY_Pin|TFT_RESET_Pin, GPIO_PIN_RESET);

  /*Configure GPIO pins : SD_CS_Pin FLASH_CS_Pin TFT_DC_Pin TFT_CS_Pin */
  GPIO_InitStruct.Pin = SD_CS_Pin|FLASH_CS_Pin|TFT_DC_Pin|TFT_CS_Pin;
  GPIO_InitStruct.Mode = GPIO_MODE_OUTPUT_PP;
  GPIO_InitStruct.Pull = GPIO_NOPULL;
  GPIO_InitStruct.Speed = GPIO_SPEED_FREQ_LOW;
  HAL_GPIO_Init(GPIOC, &GPIO_InitStruct);

  /*Configure GPIO pin : TILT_SW_Pin */
  GPIO_InitStruct.Pin = TILT_SW_Pin;
  GPIO_InitStruct.Mode = GPIO_MODE_INPUT;
  GPIO_InitStruct.Pull = GPIO_NOPULL;
  HAL_GPIO_Init(TILT_SW_GPIO_Port, &GPIO_InitStruct);

  /*Configure GPIO pins : JBC_CHANGE_Pin JBC_STBY_Pin I_ENC_B_Pin G_ENC_B_Pin */
  GPIO_InitStruct.Pin = JBC_CHANGE_Pin|JBC_STBY_Pin|I_ENC_B_Pin|G_ENC_B_Pin;
  GPIO_InitStruct.Mode = GPIO_MODE_INPUT;
  GPIO_InitStruct.Pull = GPIO_NOPULL;
  HAL_GPIO_Init(GPIOB, &GPIO_InitStruct);

  /*Configure GPIO pin : REED_SW_Pin */
  GPIO_InitStruct.Pin = REED_SW_Pin;
  GPIO_InitStruct.Mode = GPIO_MODE_INPUT;
  GPIO_InitStruct.Pull = GPIO_NOPULL;
  HAL_GPIO_Init(REED_SW_GPIO_Port, &GPIO_InitStruct);

  /*Configure GPIO pins : AC_RELAY_Pin TFT_RESET_Pin */
  GPIO_InitStruct.Pin = AC_RELAY_Pin|TFT_RESET_Pin;
  GPIO_InitStruct.Mode = GPIO_MODE_OUTPUT_PP;
  GPIO_InitStruct.Pull = GPIO_NOPULL;
  GPIO_InitStruct.Speed = GPIO_SPEED_FREQ_LOW;
  HAL_GPIO_Init(GPIOA, &GPIO_InitStruct);

}

void Error_Handler(void)
{
  __disable_irq();
  while (1)
  {
  }
}
